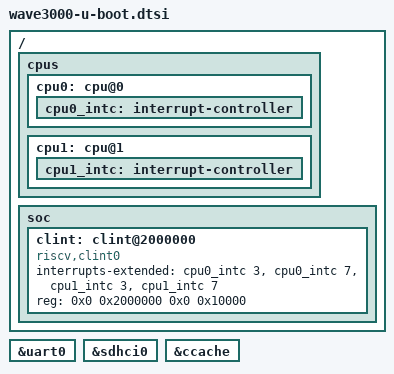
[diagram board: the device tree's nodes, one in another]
// SPDX-License-Identifier: (GPL-2.0 OR MIT)
/*
 * (C) Copyright 2023-2024 Siliconwaves, Inc
 */

/ {
	cpus {
		u-boot,dm-spl;
		cpu0: cpu@0 {
			u-boot,dm-spl;
			status = "okay";
			cpu0_intc: interrupt-controller {
				u-boot,dm-spl;
			};
		};
		cpu1: cpu@1 {
			u-boot,dm-spl;
			status = "okay";
			cpu1_intc: interrupt-controller {
				u-boot,dm-spl;
			};
		};
	};

	soc {
		u-boot,dm-spl;
		clint: clint@2000000 {
			compatible = "riscv,clint0";
			interrupts-extended = <&cpu0_intc 3 &cpu0_intc 7
					       &cpu1_intc 3 &cpu1_intc 7 >;
			reg = <0x0 0x2000000 0x0 0x10000>;
			u-boot,dm-spl;
		};
	};
};

&uart0 {
	u-boot,dm-spl;
};

&sdhci0 {
	u-boot,dm-spl;
};

&ccache {
	status = "okay";
};
